AUTOSAR XML (schema 4-0-3)
standard types defined: Boolean, UInt16, UInt32, UInt8
package /AUTOSAR_Platform/DataConstrs
  range DC_Boolean: raw 0..1
  range DC_UInt16: raw 0..65535
  range DC_UInt8: raw 0..255
package /PATAC/MSM/ComponentTypes
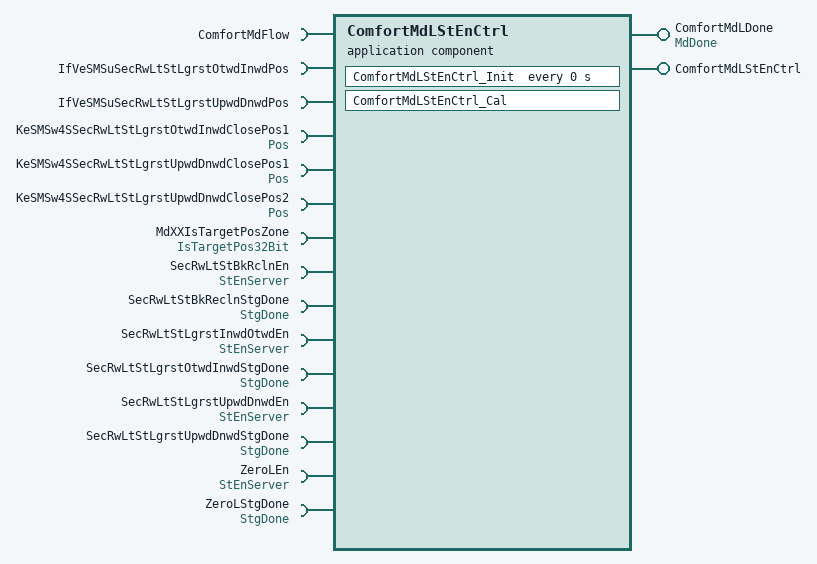
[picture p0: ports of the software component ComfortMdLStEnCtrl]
  application sw component type ComfortMdLStEnCtrl
    provide port ComfortMdLDone: nonqueued-sender-com-spec{data-element=MdDone/Val, init-value=0}, provided-interface=MdDone
    provide port ComfortMdLStEnCtrl: server-com-spec{operation=ComfortMdLStEnCtrl/Cal, queue-length=1}, provided-interface=ComfortMdLStEnCtrl
    15 x require port:
      ComfortMdFlow: client-com-spec=ComfortMdFlow/Cal, required-interface=ComfortMdFlow
      IfVeSMSuSecRwLtStLgrstOtwdInwdPos: nonqueued-receiver-com-spec{data-element=IfVeSMSuSecRwLtStLgrstOtwdInwdPos/Val, filter=data-filter-type=ALWAYS, init-value=0}, required-interface=IfVeSMSuSecRwLtStLgrstOtwdInwdPos
      IfVeSMSuSecRwLtStLgrstUpwdDnwdPos: nonqueued-receiver-com-spec{data-element=IfVeSMSuSecRwLtStLgrstUpwdDnwdPos/Val, filter=data-filter-type=ALWAYS, init-value=0}, required-interface=IfVeSMSuSecRwLtStLgrstUpwdDnwdPos
      KeSMSw4SSecRwLtStLgrstOtwdInwdClosePos1: parameter-require-com-spec{init-value=0, parameter=Val}, required-interface=Pos
      KeSMSw4SSecRwLtStLgrstUpwdDnwdClosePos1: parameter-require-com-spec{init-value=0, parameter=Val}, required-interface=Pos
      KeSMSw4SSecRwLtStLgrstUpwdDnwdClosePos2: parameter-require-com-spec{init-value=0, parameter=Val}, required-interface=Pos
      MdXXIsTargetPosZone: nonqueued-receiver-com-spec{data-element=IsTargetPos32Bit/Val, filter=data-filter-type=ALWAYS, init-value=0}, required-interface=IsTargetPos32Bit
      SecRwLtStBkRclnEn: required-com-specs=[Clear, Get, Set], required-interface=StEnServer
      SecRwLtStBkReclnStgDone: nonqueued-receiver-com-spec{data-element=StgDone/Val, filter=data-filter-type=ALWAYS, init-value=0}, required-interface=StgDone
      SecRwLtStLgrstInwdOtwdEn: required-com-specs=[Clear, Get, Set], required-interface=StEnServer
      SecRwLtStLgrstOtwdInwdStgDone: nonqueued-receiver-com-spec{data-element=StgDone/Val, filter=data-filter-type=ALWAYS, init-value=0}, required-interface=StgDone
      SecRwLtStLgrstUpwdDnwdEn: required-com-specs=[Clear, Get, Set], required-interface=StEnServer
      SecRwLtStLgrstUpwdDnwdStgDone: nonqueued-receiver-com-spec{data-element=StgDone/Val, filter=data-filter-type=ALWAYS, init-value=0}, required-interface=StgDone
      ZeroLEn: required-com-specs=[Clear, Get, Set], required-interface=StEnServer
      ZeroLStgDone: nonqueued-receiver-com-spec{data-element=StgDone/Val, filter=data-filter-type=ALWAYS, init-value=0}, required-interface=StgDone
    behavior ComfortMdLStEnCtrl_InternalBehavior
      operation invoked event OIT_LgrstOpnLStEnCtrl_Cal_ComfortMdLStEnCtrl_Cal: start-on-event=ComfortMdLStEnCtrl_Cal, operation=ComfortMdLStEnCtrl.Cal
      timing event LgrstOpnLStEnCtrl_InitEvent: start-on-event=ComfortMdLStEnCtrl_Init, period=0
      runnable ComfortMdLStEnCtrl_Cal
        data-receive-point-by-arguments:
          7 x access:
            REC_IfVeSMSuSecRwLtStLgrstOtwdInwdPos_Val: accessed-variable=IfVeSMSuSecRwLtStLgrstOtwdInwdPos.Val
            REC_IfVeSMSuSecRwLtStLgrstUpwdDnwdPos_Val: accessed-variable=IfVeSMSuSecRwLtStLgrstUpwdDnwdPos.Val
            REC_MdXXIsTargetPosZone_Val: accessed-variable=MdXXIsTargetPosZone.Val
            REC_SecRwLtStBkReclnStgDone_Val: accessed-variable=SecRwLtStBkReclnStgDone.Val
            REC_SecRwLtStLgrstOtwdInwdStgDone_Val: accessed-variable=SecRwLtStLgrstOtwdInwdStgDone.Val
            REC_SecRwLtStLgrstUpwdDnwdStgDone_Val: accessed-variable=SecRwLtStLgrstUpwdDnwdStgDone.Val
            REC_ZeroLStgDone_Val: accessed-variable=ZeroLStgDone.Val
        data-send-points:
          access SEND_ComfortMdLDone_Val: accessed-variable=ComfortMdLDone.Val
        parameter access PA_KeSMSw4SSecRwLtStLgrstOtwdInwdClosePos1_Val: accessed-parameter=KeSMSw4SSecRwLtStLgrstOtwdInwdClosePos1.Val
        parameter access PA_KeSMSw4SSecRwLtStLgrstUpwdDnwdClosePos1_Val: accessed-parameter=KeSMSw4SSecRwLtStLgrstUpwdDnwdClosePos1.Val
        parameter access PA_KeSMSw4SSecRwLtStLgrstUpwdDnwdClosePos2_Val: accessed-parameter=KeSMSw4SSecRwLtStLgrstUpwdDnwdClosePos2.Val
        9 x sync call, all with timeout=0:
          SC_ComfortMdFlow_Cal: operation=ComfortMdFlow.Cal
          SC_SecRwLtStBkRclnEn_Clear: operation=SecRwLtStBkRclnEn.Clear
          SC_SecRwLtStBkRclnEn_Set: operation=SecRwLtStBkRclnEn.Set
          SC_SecRwLtStLgrstInwdOtwdEn_Clear: operation=SecRwLtStLgrstInwdOtwdEn.Clear
          SC_SecRwLtStLgrstInwdOtwdEn_Set: operation=SecRwLtStLgrstInwdOtwdEn.Set
          SC_SecRwLtStLgrstUpwdDnwdEn_Clear: operation=SecRwLtStLgrstUpwdDnwdEn.Clear
          SC_SecRwLtStLgrstUpwdDnwdEn_Set: operation=SecRwLtStLgrstUpwdDnwdEn.Set
          SC_ZeroLEn_Clear: operation=ZeroLEn.Clear
          SC_ZeroLEn_Set: operation=ZeroLEn.Set
      runnable ComfortMdLStEnCtrl_Init
        parameter access PA_KeSMSw4SSecRwLtStLgrstOtwdInwdClosePos1_Val: accessed-parameter=KeSMSw4SSecRwLtStLgrstOtwdInwdClosePos1.Val
        parameter access PA_KeSMSw4SSecRwLtStLgrstUpwdDnwdClosePos1_Val: accessed-parameter=KeSMSw4SSecRwLtStLgrstUpwdDnwdClosePos1.Val
        parameter access PA_KeSMSw4SSecRwLtStLgrstUpwdDnwdClosePos2_Val: accessed-parameter=KeSMSw4SSecRwLtStLgrstUpwdDnwdClosePos2.Val
  swc implementation ComfortMdLStEnCtrl_Implementation: behavior=ComfortMdLStEnCtrl_InternalBehavior
    code-descriptors:
      code Default: artifact-descriptors=autosar-engineering-object={short-label=Default, category=SWSRC}
package /PATAC/MSM/ModeAdjust/CalPortInterface
  parameter interface Pos
    parameter data prototype Val: sw-calibration-access=READ-WRITE, type=UInt16
package /PATAC/MSM/ModeAdjust/PortInterface
  client server interface ComfortMdFlow
    operation Cal
      14 x arg, all with server-argument-impl-policy=USE-ARGUMENT-TYPE:
        LgrstUpwdDnwdPos: type=UInt16, direction=IN
        LgrstUpwdDnwdClosePos1: type=UInt16, direction=IN
        LgrstUpwdStgDone: type=Implementation/Boolean, direction=IN
        ZeroStgDone: type=Implementation/Boolean, direction=IN
        LgrstInwdStgDone: type=Implementation/Boolean, direction=IN
        Failflg: type=Implementation/Boolean, direction=OUT
        LgrstInwdOtwdEn: type=Implementation/Boolean, direction=OUT
        LgrstUpwdDnwdEn: type=Implementation/Boolean, direction=OUT
        ZeroEn: type=Implementation/Boolean, direction=OUT
        BkReclnStgDone: type=DataTypes/Boolean, direction=IN
        BkReclnEn: type=DataTypes/Boolean, direction=OUT
        LgrstUpwdDnwdClosePos2: type=UInt16, direction=IN
        LgrstInwdOtwdClosePos1: type=UInt16, direction=IN
        LgrstInwdOtwdPos: type=UInt16, direction=IN
  client server interface ComfortMdLStEnCtrl
    operation Cal
  client server interface StEnServer
    operation Clear
      arg data: type=UInt8, direction=IN, server-argument-impl-policy=USE-ARGUMENT-TYPE
    operation Get
      arg data: type=UInt32, direction=OUT, server-argument-impl-policy=USE-ARGUMENT-TYPE
    operation Set
      arg data: type=UInt8, direction=IN, server-argument-impl-policy=USE-ARGUMENT-TYPE
  sender receiver interface IsTargetPos32Bit: invalidation-policy{data-element=IsTargetPos32Bit/Val, handle-invalid=DONT-INVALIDATE}
    data Val: type=UInt32
  sender receiver interface MdDone: invalidation-policy{data-element=MdDone/Val, handle-invalid=DONT-INVALIDATE}
    data Val: type=UInt8
  sender receiver interface StgDone: invalidation-policy{data-element=StgDone/Val, handle-invalid=DONT-INVALIDATE}
    data Val: type=Implementation/Boolean
package /PATAC/MSM/PortInterfaces
  sender receiver interface IfVeSMSuSecRwLtStLgrstOtwdInwdPos: invalidation-policy{data-element=IfVeSMSuSecRwLtStLgrstOtwdInwdPos/Val, handle-invalid=DONT-INVALIDATE}
    data Val: type=UInt16
  sender receiver interface IfVeSMSuSecRwLtStLgrstUpwdDnwdPos: invalidation-policy{data-element=IfVeSMSuSecRwLtStLgrstUpwdDnwdPos/Val, handle-invalid=DONT-INVALIDATE}
    data Val: type=UInt16
